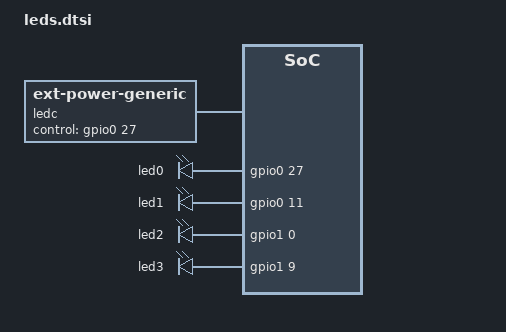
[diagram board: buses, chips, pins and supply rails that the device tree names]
/*
 * copyright (c) 2025 ZMK project contributors
 *
 * SPDX-license-identifier: MIT
 */

#include <dt-bindings/led/led.h>

/ {
    aliases {
        led-lock = &ledc;
        led-red = &led1;
        led-green = &led2;
        led-blue = &led3;
    };

    ledc: EXT_POWER {
        compatible = "zmk,ext-power-generic";
        control-gpios = <&gpio0 27 (GPIO_ACTIVE_HIGH)>;
    };

    leds {
        compatible = "gpio-leds";
        status = "okay";

        /* CAPS / NUM / SCROLL LOCK LED */
        led0: led0 {
            gpios = <&gpio0 27 (GPIO_ACTIVE_HIGH)>;
        };

        /* status LED (red) */
        led1: led1 {
            gpios = <&gpio0 11 (GPIO_ACTIVE_HIGH)>;
        };

        /* status LED (green) */
        led2: led2 {
            gpios = <&gpio1 0  (GPIO_ACTIVE_HIGH)>;
        };

        /* status LED (blue) */
        led3: led3 {
            gpios = <&gpio1 9  (GPIO_ACTIVE_HIGH)>;
        };
    };
};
